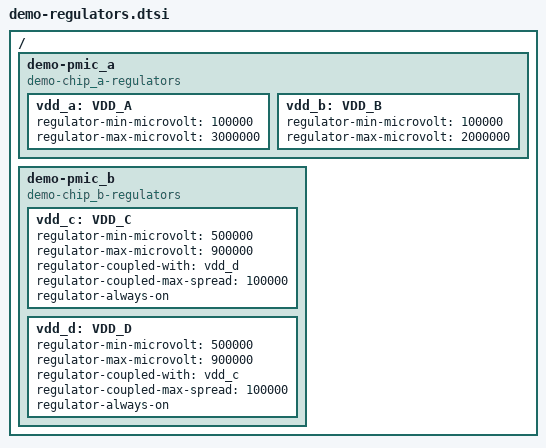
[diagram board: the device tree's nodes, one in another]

/ {
	demo-pmic_a {
		compatible = "demo-chip_a-regulators";
		
		vdd_a: VDD_A {
			regulator-min-microvolt = <100000>;
			regulator-max-microvolt = <3000000>;
		};

		vdd_b: VDD_B {
			regulator-min-microvolt = <100000>;
			regulator-max-microvolt = <2000000>;
		};
	};

	demo-pmic_b {
		compatible = "demo-chip_b-regulators";
		
		vdd_c: VDD_C {
			regulator-min-microvolt = <500000>;
			regulator-max-microvolt = <900000>;
			regulator-coupled-with = <&vdd_d>;
			regulator-coupled-max-spread = <100000>;
			regulator-always-on;
		};

		vdd_d: VDD_D {
			regulator-min-microvolt = <500000>;
			regulator-max-microvolt = <900000>;
			regulator-coupled-with = <&vdd_c>;
			regulator-coupled-max-spread = <100000>;
			regulator-always-on;
		};
	};
};
